# R7FA4L1BD register map
Vendor: Renesas Electronics Corporation; Series: RA4; File version: 0.90.02
CPU: CM33 r0p4, little endian, MPU, FPU, VTOR, 4 interrupt priority bits, 96 interrupts
Registers are 32-bit, read-write, reset 0x0 unless marked. A register's access mark holds for its fields unless they carry their own. Offsets are from the block's base; [hi:lo] are bit positions; {n}, {i} and the like mark numbered series.

## CACHE
Base 0x40007000
0x00 CCACTL — C,Cache Control Register
  [0] ENC — C,Cache Enable
0x04 CCAFCT — C,Cache Flush Control Register
  [0] FC — C,Cache Flush
0x08 CCALCF reset 0x1 — C,Cache Line Configuration Register
  [1:0] CC — C,Cache Line Size
0x40 SCACTL — S,Cache Control Register
  [0] ENS — S,Cache Enable
0x44 SCAFCT — S,Cache Flush Control Register
  [0] FS — S,Cache Flush
0x48 SCALCF reset 0x1 — S,Cache Line Configuration Register
  [1:0] CS — S,Cache Line Size
0x200 CAPOAD — Cache Parity Error Operation After Detection Register
  [0] OAD — Operation after Detection
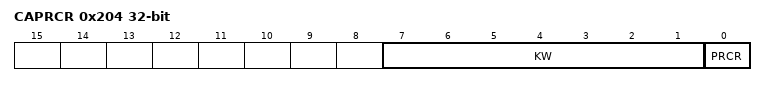
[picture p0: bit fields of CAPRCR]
0x204 CAPRCR — Cache Protection Register
  [7:1] KW — Write key code
  [0] PRCR — Register Write Control

## CPSCU — CPU System Security Control Unit
Base 0x40008000
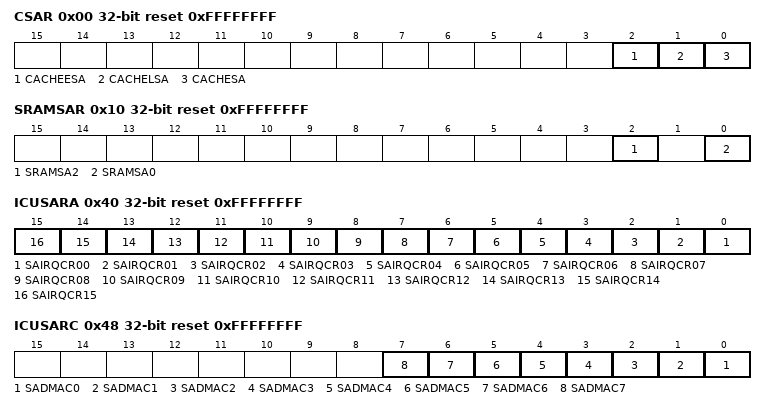
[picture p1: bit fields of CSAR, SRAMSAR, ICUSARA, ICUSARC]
0x00 CSAR reset 0xFFFFFFFF — Cache Security Attribution Register
  [2] CACHEESA — Security Attributes of Registers for Cache Error
  [1] CACHELSA — Security Attributes of Registers for Cache Line Configuration
  [0] CACHESA — Security Attributes of Registers for Cache Control
0x10 SRAMSAR reset 0xFFFFFFFF — SRAM Security Attribution Register
  [2] SRAMSA2 — Security attributes of registers for ECC Relation
  [0] SRAMSA0 — Security attributes of registers for SRAM Protection
0x30 DTCSAR reset 0xFFFFFFFF — DTC Controller Security Attribution Register
  [0] DTCSTSA — DTC Security Attribution
0x34 DMACSAR reset 0xFFFFFFFF — DMAC Controller Security Attribution Register
  [0] DMASTSA — DMAST Security Attribution
0x40 ICUSARA reset 0xFFFFFFFF — Interrupt Controller Unit Security Attribution Register A
  [n] SAIRQCR{n:02} (n=0..15) — Security attributes of registers for the IRQCRn register
0x44 ICUSARB reset 0xFFFFFFFF — Interrupt Controller Unit Security Attribution Register B
  [0] SANMI — Security attributes of registers for nonmaskable interrupt
0x48 ICUSARC reset 0xFFFFFFFF — Interrupt Controller Unit Security Attribution Register C
  [n] SADMAC{n} (n=0..7) — Security attributes of registers for DMAC channel
0x4C ICUSARD reset 0xFFFFFFFF — Interrupt Controller Unit Security Attribution Register D
  [0] SASELSR0 — Security attributes of registers for SELSR0
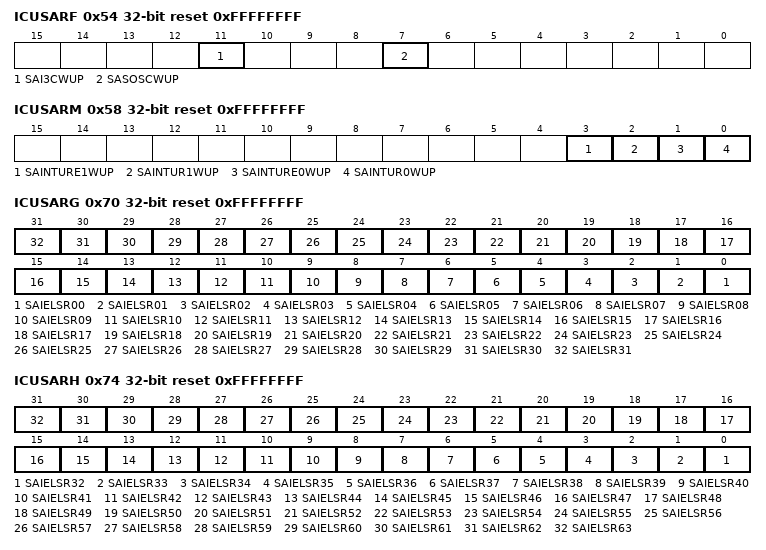
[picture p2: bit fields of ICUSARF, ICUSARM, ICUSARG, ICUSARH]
0x54 ICUSARF reset 0xFFFFFFFF — Interrupt Controller Unit Security Attribution Register F
  [11] SAI3CWUP — Security attributes of registers for WUPEN1.b11
  [7] SASOSCWUP — Security attributes of registers for WUPEN1.b7
0x58 ICUSARM reset 0xFFFFFFFF — Interrupt Controller Unit Security Attribution Register M
  [3] SAINTURE1WUP — Security attributes of registers for WUPEN2.b3
  [2] SAINTUR1WUP — Security attributes of registers for WUPEN2.b2
  [1] SAINTURE0WUP — Security attributes of registers for WUPEN2.b1
  [0] SAINTUR0WUP — Security attributes of registers for WUPEN2.b0
0x70 ICUSARG reset 0xFFFFFFFF — Interrupt Controller Unit Security Attribution Register G
  [n] SAIELSR{n:02} (n=0..31) — Security attributes of registers for IELSR31 to IELSR0
0x74 ICUSARH reset 0xFFFFFFFF — Interrupt Controller Unit Security Attribution Register H
  [n-32] SAIELSR{n} (n=32..63) — Security attributes of registers for IELSR63 to IELSR32
0x100 BUSSARA reset 0xFFFFFFFF — BUS Security Attribution Register A
  [0] BUSSA0 — BUS Security Attribution A0
0x104 BUSSARB reset 0xFFFFFFFF — BUS Security Attribution Register B
  [0] BUSSB0 — BUS Security Attribution B0
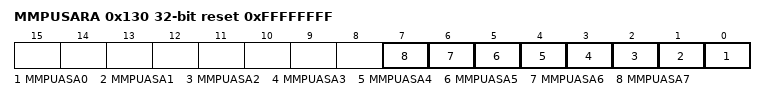
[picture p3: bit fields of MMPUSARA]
0x130 MMPUSARA reset 0xFFFFFFFF — Master Memory Protection Unit Security Attribution Register A
  [n] MMPUASA{n} (n=0..7) — MMPUA Security Attribution (n = 0 to 7)
0x134 MMPUSARB reset 0xFFFFFFFF — Master Memory Protection Unit Security Attribution Register B
  [0] MMPUBSA0 — MMPUB Security Attribution
0x180 TZFSAR reset 0xFFFFFFFE — TrustZone Filter Security Attribution Register
  [0] TZFSA0 — Security attributes of registers for TrustZone Filter
0x1B0 CPUDSAR reset 0xFFFFFFFE — CPU Debug Security Attribution Register
  [0] CPUDSA0 — CPU Debug Security Attribution 0
